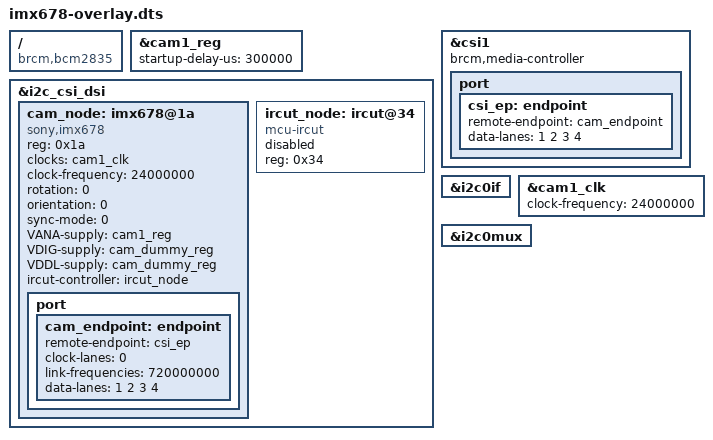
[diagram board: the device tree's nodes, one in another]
// SPDX-License-Identifier: GPL-2.0-only
// Definitions for IMX678 camera module on VC I2C bus
/dts-v1/;
/plugin/;
/{
	compatible = "brcm,bcm2835";

	fragment@0 {
		target = <&cam_endpoint>;
		__overlay__ {
			data-lanes = <1 2 3 4>;
		};
	};

	fragment@1 {
		target = <&cam_endpoint>;
		__dormant__ {
			data-lanes = <1 2>;
		};
	};

	fragment@2 {
		target = <&csi_ep>;
		__overlay__ {
			data-lanes = <1 2 3 4>;
		};
	};

	fragment@3 {
		target = <&csi_ep>;
		__dormant__ {
			data-lanes = <1 2>;
		};
	};

	reg_frag: fragment@4 {
		target = <&cam1_reg>;
		cam_reg: __overlay__ {
			startup-delay-us = <300000>;
		};
	};

	reg_alwayson_frag: fragment@99 {
		target = <&cam1_reg>;
		__dormant__ {
			regulator-always-on;
		};
	};


	i2c_frag: fragment@100 {
		target = <&i2c_csi_dsi>;
		__overlay__ {
			#address-cells = <1>;
			#size-cells = <0>;
			status = "okay";

			cam_node: imx678@1a {
				compatible = "sony,imx678";
				reg = <0x1a>;
				clocks = <&cam1_clk>;
				clock-names = "xclk";
				clock-frequency = <24000000>;

				rotation = <0>;
				orientation = <0>;
				sync-mode = <0>;

				VANA-supply = <&cam1_reg>;	/* 3.3v */
				VDIG-supply = <&cam_dummy_reg>;	/* 1.1v */
				VDDL-supply = <&cam_dummy_reg>;	/* 1.8v */

				ircut-controller = <&ircut_node>;

				port {
					cam_endpoint: endpoint {
						remote-endpoint = <&csi_ep>;
						clock-lanes = <0>;
						link-frequencies =
							/bits/ 64 <720000000>;
					};
				};
			};

			/* IR-cut controller – disabled by default */
        	ircut_node: ircut@34 {
                compatible = "mcu-ircut";
                reg        = <0x34>;
                status     = "disabled";
            };

		};
	};

	csi_frag: fragment@101 {
		target = <&csi1>;
		csi: __overlay__ {
			status = "okay";
			brcm,media-controller;

			port {
				csi_ep: endpoint {
					remote-endpoint = <&cam_endpoint>;
				};
			};
		};
	};

	fragment@102 {
		target = <&i2c0if>;
		__overlay__ {
			status = "okay";
		};
	};

	clk_frag: fragment@103 {
		target = <&cam1_clk>;
		cam_clk: __overlay__ {
			status = "okay";
			clock-frequency = <24000000>;
		};
	};

	fragment@104 {
		target = <&i2c0mux>;
		__overlay__ {
			status = "okay";
		};
	};

	__overrides__ {
		2lane = <0>, "-0+1-2+3";
		always-on = <0>, "+99";
		rotation = <&cam_node>,"rotation:0";
		orientation = <&cam_node>,"orientation:0";
		sync-mode = <&cam_node>,"sync-mode:0";
		media-controller = <&csi>,"brcm,media-controller?";
		cam0 = <&i2c_frag>, "target:0=",<&i2c_csi_dsi0>,
		       <&csi_frag>, "target:0=",<&csi0>,
		       <&clk_frag>, "target:0=",<&cam0_clk>,
		       <&cam_node>, "clocks:0=",<&cam0_clk>,
		       <&reg_alwayson_frag>, "target:0=",<&cam0_reg>,
		       <&cam_node>, "VANA-supply:0=",<&cam0_reg>;
		mono = <&cam_node>,"mono-mode:0=1";
		hdr = <&cam_node>,"clearHDR-mode:0=1";
		link-frequency = <&cam_endpoint>,"link-frequencies#0";
        ircut        = <&ircut_node>,"status=okay",
                       <&cam_node>,"ircut-mode:0=1";
        ircut_addr   = <&ircut_node>,"reg:0";
	};
};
